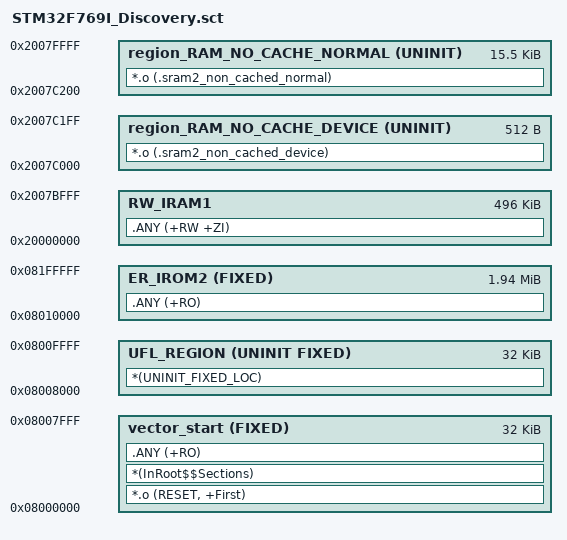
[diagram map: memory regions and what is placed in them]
; *************************************************************
; *** Scatter-Loading Description File generated by uVision ***
; *************************************************************
/* SRAM2 : [0x2007C000, 0x2007FFFF] : 16 KBytes                                 */
/*         [0x2007C000,0x2007C1FF]  : 512 Bytes     : Ethernet dma descripteurs */
/*         [0x2007C200,0x2007FFFF]  : 15.5 KBytes   : Ethernet Buffers          */

LR_IROM1 0x08000000 0x00008000  {
  vector_start 0x08000000 FIXED 0x00008000  {
   *.o (RESET, +First)
   *(InRoot$$Sections)
   .ANY (+RO)
  }
}

   

LR_IROM2 0x08008000 0x8000  {
; Definition of the static memory section for the user configuration: TLS certificates, key, and wifi configuration data.
; A whole sector must be reserved so that the linker does not place initialized data there, which 
; would cause a sector erase when the firmware image is programmed.
; This mapping is valid whatever the bank organization:
;    Seen as 1 x 32k sector at 0x08008000 in single bank case
;    Seen as 2 x 16k sectors at 0x08008000 in dual bank case.
  UFL_REGION 0x08008000 UNINIT FIXED 0x8000  {    ; Reserve a chunck for user config.
    *(UNINIT_FIXED_LOC)   
  }
}

LR_IROM3 0x08010000 0x001F0000  {
  ER_IROM2 0x08010000 FIXED 0x001F0000  {
   .ANY (+RO)
  }

  RW_IRAM1 0x20000000 0x0007C000  {  ; RW data
   .ANY (+RW +ZI)
  }
}

LR_SRAM2 0x2007C000  0x4000 {
  region_RAM_NO_CACHE_DEVICE 0x2007C000 UNINIT  0x00000200 { ; Ethernet DMA descriptors
    *.o (.sram2_non_cached_device)
  }

  region_RAM_NO_CACHE_NORMAL 0x2007C200 UNINIT 0x00003E00 { ; Ethernet buffers
    *.o (.sram2_non_cached_normal)
  }
}
